# ble_rfcore_mdm_secure register map
Vendor: Texas Instruments
Peripheral module from a debugger description file (folder CC35X1).
Registers are 32-bit, access per field, reset 0x0 unless marked. A register's access mark holds for its fields unless they carry their own. Offsets are as the file gives them; lines under a group give offsets from that group; [hi:lo] are bit positions; {n}, {i} and the like mark numbered series; 'fields as' and 'values as' point back to an identical list; <NAME> marks a mode.

## ble_rfcore_mdm_secure (part 1 of 2)
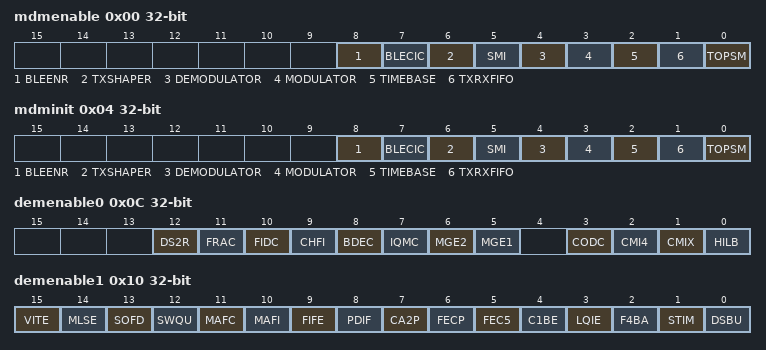
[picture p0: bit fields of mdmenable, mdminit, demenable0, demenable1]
0x00 mdmenable — Modem Enable Register
  [8] BLEENR rw — Enables the BLE ENR - Exp And Ramp (module location is in ble_top/ble_rfext/...)
  [7] BLECIC rw — Enables the BLE CIC (module location is in ble_top/ble_rfext/...)
  [6] TXSHAPER rw — Enables the BLE Tx-Shaper (module location is in ble_top/ble_rfext/...)
  [5] SMI rw — Enables the Serial Modem Interface
  [4] DEMODULATOR rw — Enables the Demodulator
  [3] MODULATOR rw — Enables the Modulator
  [2] TIMEBASE rw — Enables the Modem Timebase
  [1] TXRXFIFO rw — Enables the TX/RX FIFO
  [0] TOPSM rw — Enables the TOPsm (MCE)
0x04 mdminit — Modem Initialize Register - Each bit Initialize a specific MDM module Register type is WI ("Write Impulse"): Write generate 1-clock cycle pulse, Read 0.
  [8] BLEENR wo — Synch reset of the BLE ENR - Exp And Ramp (module location is in ble_top/ble_rfext/...)
  [7] BLECIC wo — Synch reset of the BLE CIC (module location is in ble_top/ble_rfext/...)
  [6] TXSHAPER wo — Synch reset for the BLE Tx-Shaper (module location is in ble_top/ble_rfext/...)
  [5] SMI wo — Synch reset Serial Modem Interface
  [4] DEMODULATOR wo — Synch reset Demodulator
  [3] MODULATOR wo — Synch reset Modulator
  [2] TIMEBASE wo — Synch reset Modem Timebase
  [1] TXRXFIFO wo — Synch reset TX/RX FIFO
  [0] TOPSM wo — Synch reset TOPsm (MCE)
0x08 mdmpdreq — Modem Power Down Request Register
  [0] TOPSMPDREQ rw — Requests power-down for TOPsm core. If the TOPsm has an ongoing memory access, the hardware will safely gate the clock after the transaction has completed.
0x0C demenable0 — Demodulator Enable Register 0
  [12] DS2R rw — Enables the DEC-S2R module
  [11] FRAC rw — Enables the fractional resampler
  [10] FIDC rw — Enables the fine DC estimator
  [9] CHFI rw — Enables the channel filter
  [8] BDEC rw — Enables the cascaded dec-by-2 stages (bde1 and bde2)
  [7] IQMC rw — Enables the IQ mismatch compensation
  [6] MGE2 rw — Enables the magnitude estimator engine #2
  [5] MGE1 rw — Enables the magnitude estimator engine #1
  [3] CODC rw — Enables the coarse DC estimator
  [2] CMI4 rw — Enables the 1/4 complex mixer
  [1] CMIX rw — Enables the N/1024 complex mixer
  [0] HILB rw — Enables the Hilbert filter
0x10 demenable1 — Demodulator Enable Register 1
  [15] VITE rw — Enables the Viterbi module
  [14] MLSE rw — Enables the MLSE module
  [13] SOFD rw — Enables the soft decision module
  [12] SWQU rw — Enables the sync word qualifier
  [11] MAFC rw — Enables the manual frequency compensation module
  [10] MAFI rw — Enables the matched filter
  [9] FIFE rw — Enables the fine frequency offset estimator
  [8] PDIF rw — Enables the phase differentiation
  [7] CA2P rw — Enables the cart 2 polar conversion
  [6] FECP rw — Enables the fecp module
  [5] FEC5 rw — Enables the fec5 module
  [4] C1BE rw — Enables the correlation 1-bit engine
  [3] LQIE rw — Enables the LQI engine
  [2] F4BA rw — Enables the clock-domain crossing fifo
  [1] STIM rw — Enables the symbol timing tracker
  [0] DSBU rw — Enables the dynamic sample buffer
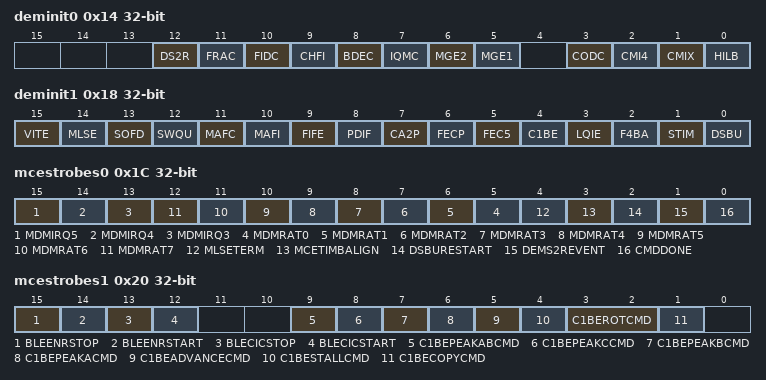
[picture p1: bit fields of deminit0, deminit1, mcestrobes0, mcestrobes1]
0x14 deminit0 — Demodulator Initialize Register 0 - Each bit Initialize a specific Demodulator module. Register type is WI ("Write Impulse"): Write generate 1-clock cycle pulse, Read 0.
  [12] DS2R wo — Synch reset DEC-S2R module
  [11] FRAC wo — Synch reset fractional resampler
  [10] FIDC wo — Synch reset fine DC estimator
  [9] CHFI wo — Synch reset channel filter
  [8] BDEC wo — Synch reset cascaded dec-by-2 stages (bde1 and bde2)
  [7] IQMC wo — Synch reset IQ mismatch compensation
  [6] MGE2 wo — Synch reset magnitude estimator engine #2
  [5] MGE1 wo — Synch reset magnitude estimator engine #1
  [3] CODC wo — Synch reset coarse DC estimator
  [2] CMI4 wo — Synch reset 1/4 complex mixer
  [1] CMIX wo — Synch reset N/1024 complex mixer
  [0] HILB wo — Synch reset Hilbert filter
0x18 deminit1 — Demodulator Initialize Register 1 - Each bit Initialize a specific Demodulator module. Register type is WI ("Write Impulse"): Write generate 1-clock cycle pulse, Read 0.
  [15] VITE wo — Synch reset Viterbi Module
  [14] MLSE wo — Synch reset MLSE module
  [13] SOFD wo — Synch reset soft decision module
  [12] SWQU wo — Synch reset sync word qualifyer
  [11] MAFC wo — Synch reset manual frequency compensation module
  [10] MAFI wo — Synch reset matched filter
  [9] FIFE wo — Synch reset fine frequency offset estimator
  [8] PDIF wo — Synch reset phase differentiation
  [7] CA2P wo — Synch reset cart 2 polar conversion
  [6] FECP wo — Synch reset fecp module
  [5] FEC5 wo — Synch reset fec5 module
  [4] C1BE wo — Synch reset correlation 1-bit engine
  [3] LQIE wo — Synch reset LQI engine
  [2] F4BA wo — Synch reset clock-domain crossing fifo
  [1] STIM wo — Synch reset symbol timing tracker
  [0] DSBU wo — Synch reset dynamic sample buffer
0x1C mcestrobes0 — Modem Command Engine (MCE) Strobe Register 0 - Each bit Strob a specific event. Register type is WI ("Write Impulse"): Write generate 1-clock cycle pulse, Read 0.
  [15] MDMIRQ5 wo — Firmware defined MDM IRQ 5 event
  [14] MDMIRQ4 wo — Firmware defined MDM IRQ 4 event
  [13] MDMIRQ3 wo — Firmware defined MDM IRQ 3 event
  [n+5] MDMRAT{n} wo (n=0..7) — Firmware defined MDM RAT {n} event
  [4] MLSETERM wo — Terminate MLSE unit
  [3] MCETIMBALIGN wo — Align the 1baud to the next 4baud event
  [2] DSBURESTART wo — Restart DSBU
  [1] DEMS2REVENT wo — Dem-S2R Trigger Event
  [0] CMDDONE wo — Signal command done to CPE
0x20 mcestrobes1 — Modem Command Engine (MCE) Strobe Register 1 - Each bit Strob a specific event. Register type is WI ("Write Impulse"): Write generate 1-clock cycle pulse, Read 0.
  [15] BLEENRSTOP wo — Trigger BLE ENR (Exp And Ramp) Stop - Ramp-Down
  [14] BLEENRSTART wo — Trigger BLE ENR (Exp And Ramp) Start - Ramp-Up
  [13] BLECICSTOP wo — Trigger BLE CIC Stop
  [12] BLECICSTART wo — Trigger BLE CIC Start
  [9] C1BEPEAKABCMD wo — Restart C1BE peak A and B search
  [8] C1BEPEAKCCMD wo — Restart C1BE peak C search (corr C is corr A+B combined = 64 symbols = 256 samples)
  [7] C1BEPEAKBCMD wo — Restart C1BE peak B search (32 symbols = 128 samples)
  [6] C1BEPEAKACMD wo — Restart C1BE peak A search (32 symbols = 128 samples)
  [5] C1BEADVANCECMD wo — Speed up correlator autocopy with one sample
  [4] C1BESTALLCMD wo — Slow down correlator autocopy with one sample
  [3:2] C1BEROTCMD wo — Correlator rotate command to shift reg B
    0=ROT0 (No additional rotation (normal shift-right mode)); 1=ROT1R (Rotate 1 sample to the right); 2=ROT1L (Rotate 1 sample to the left); 3=ROT16R (Rotate 16 samples to the right)
  [1] C1BECOPYCMD wo — Copy contents of shift reg A into shift reg B
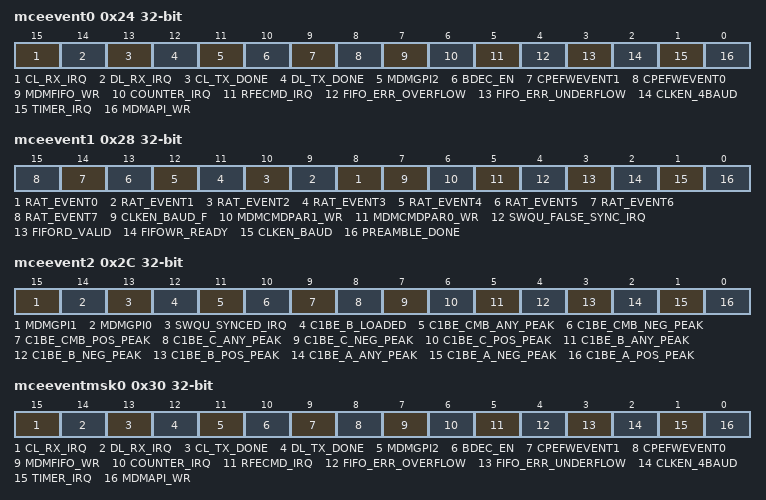
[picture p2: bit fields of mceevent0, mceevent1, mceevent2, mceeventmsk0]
0x24 mceevent0 ro — MCE Event Flag Register 0
  [15] CL_RX_IRQ — SMI serdes command word receive done
  [14] DL_RX_IRQ — SMI serdes data word receive done
  [13] CL_TX_DONE — SMI serdes command word transmit done
  [12] DL_TX_DONE — SMI serdes data word transmit done
  [11] MDMGPI2 — External input event line RFC_GPI_2 from IOC.
  [10] BDEC_EN — BDEC output enable event
  [9] CPEFWEVENT1 — Firmware defined event 1 from CPE
  [8] CPEFWEVENT0 — Firmware defined event 0 from CPE
  [7] MDMFIFO_WR — A write to the modem FIFO (via MDMFIFOWR register), probably by CPE
  [6] COUNTER_IRQ — Counter value reached in local timer
  [5] RFECMD_IRQ — New command from RFE received in RFERCEV register
  [4] FIFO_ERR_OVERFLOW — Modem FIFO overflow error event
  [3] FIFO_ERR_UNDERFLOW — Modem FIFO underflow error event
  [2] CLKEN_4BAUD — Clock enable event at 4 times baud rate
  [1] TIMER_IRQ — Timer period expired in local timer
  [0] MDMAPI_WR — New command from CPE has been written in MDMAPI register
0x28 mceevent1 ro — MCE Event Flag Register 1
  [n+8] RAT_EVENT{n} (n=0..7) — Radio timer event {n}
  [7] CLKEN_BAUD_F — Clock enable event at flushed baud rate
  [6] MDMCMDPAR1_WR — A write to MDMCMDPAR1 register, probably by CPE
  [5] MDMCMDPAR0_WR — A write to MDMCMDPAR0 register, probably by CPE
  [4] SWQU_FALSE_SYNC_IRQ — Sync word qualifier rejected sync due to bit errors (happens if a correlator event was due to noise)
  [3] FIFORD_VALID — Modem FIFO has valid data so a new word can be read from it, via MDMFIFORD
  [2] FIFOWR_READY — Modem FIFO is ready for more data so a new word can be written to it, via MDMFIFOWR register
  [1] CLKEN_BAUD — Clock enable event at baud rate
  [0] PREAMBLE_DONE — Preamble done interrupt from modulator
0x2C mceevent2 ro — MCE Event Flag Register 2
  [15] MDMGPI1 — External input event line RFC_GPI1 from IOC.
  [14] MDMGPI0 — External input event line RFC_GPI0 from IOC. (Also, when loopback mode is enabled in DEMDEBUG.LOOPBACKMODE, this input line represents the symbols fed to the demodulator's decode stage).
  [13] SWQU_SYNCED_IRQ — Sync word qualifier detected sync word.
  [12] C1BE_B_LOADED — C1BE correlator B loaded (by auto-copy function).
  [11] C1BE_CMB_ANY_PEAK — C1BE correlator AB combined, any peak detect: (abs(corr A) > thr A) and (abs(corr B) > thr B). Event occurs one sample after actual peak.
  [10] C1BE_CMB_NEG_PEAK — C1BE correlator AB combined, negative peak detect: (corr A < -thr A) and (corr B < -thr B). Event occurs one sample after actual peak.
  [9] C1BE_CMB_POS_PEAK — C1BE correlator AB combined, positive peak detect: (corr A > thr A) and (corr B > thr B). Event occurs one sample after actual peak.
  [8] C1BE_C_ANY_PEAK — C1BE correlator C, any peak detect: abs(corr C) > thr C. Event occurs one sample after actual peak.
  [7] C1BE_C_NEG_PEAK — C1BE correlator C, negative peak detect: corr C < -thr C. Event occurs one sample after actual peak.
  [6] C1BE_C_POS_PEAK — C1BE correlator C, positive peak detect: corr C > thr C. Event occurs one sample after actual peak.
  [5] C1BE_B_ANY_PEAK — C1BE correlator B, any peak detect: abs(corr B) > thr B. Event occurs one sample after actual peak.
  [4] C1BE_B_NEG_PEAK — C1BE correlator B, negative peak detect: corr B < -threshold B. Event occurs one sample after actual peak.
  [3] C1BE_B_POS_PEAK — C1BE correlator B, positive peak detect: corr B > threshold B. Event occurs one sample after actual peak.
  [2] C1BE_A_ANY_PEAK — C1BE correlator A, any peak detect: abs(corr A) > thr A. Event occurs one sample after actual peak.
  [1] C1BE_A_NEG_PEAK — C1BE correlator A, negative peak detect: corr A < -thr A. Event occurs one sample after actual peak.
  [0] C1BE_A_POS_PEAK — C1BE correlator A, positive peak detect: corr A > thr A. Event occurs one sample after actual peak.
0x30 mceeventmsk0 — MCE Event Mask Register 0
  [15] CL_RX_IRQ rw — Enable mask for event [MCEEVENT0.cl_rx_irq].
  [14] DL_RX_IRQ rw — Enable mask for event [MCEEVENT0.dl_rx_irq].
  [13] CL_TX_DONE rw — Enable mask for event [MCEEVENT0.cl_tx_done].
  [12] DL_TX_DONE rw — Enable mask for event [MCEEVENT0.dl_tx_done].
  [11] MDMGPI2 rw — Enable mask for event [MCEEVENT0.mdmgpi2].
  [10] BDEC_EN rw — Enable mask for event [MCEEVENT0.bdec_en].
  [9] CPEFWEVENT1 rw — Enable mask for event [MCEEVENT0.cpefwevent1].
  [8] CPEFWEVENT0 rw — Enable mask for event [MCEEVENT0.cpefwevent0].
  [7] MDMFIFO_WR rw — Enable mask for event [MCEEVENT0.mdmfifo_wr].
  [6] COUNTER_IRQ rw — Enable mask for event [MCEEVENT0.counter_irq].
  [5] RFECMD_IRQ rw — Enable mask for event [MCEEVENT0.rfecmd_irq].
  [4] FIFO_ERR_OVERFLOW rw — Enable mask for event [MCEEVENT0.fifo_err_overflow].
  [3] FIFO_ERR_UNDERFLOW rw — Enable mask for event [MCEEVENT0.fifo_err_underflow].
  [2] CLKEN_4BAUD rw — Enable mask for event [MCEEVENT0.clken_4baud].
  [1] TIMER_IRQ rw — Enable mask for event [MCEEVENT0.timer_irq].
  [0] MDMAPI_WR rw — Enable mask for event [MCEEVENT0.mdmapi_wr].
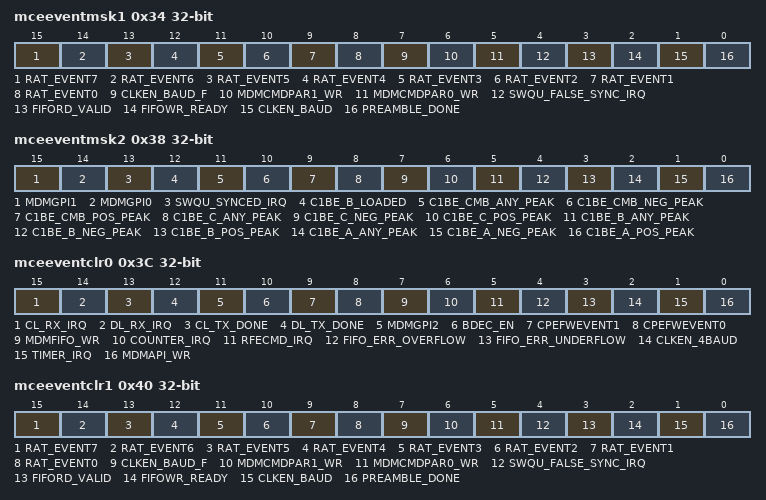
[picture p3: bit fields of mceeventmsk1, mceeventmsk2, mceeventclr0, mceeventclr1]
0x34 mceeventmsk1 — MCE Event Mask Register 1
  [15] RAT_EVENT7 rw — Enable mask for event [MCEEVENT1.rat_event7].
  [14] RAT_EVENT6 rw — Enable mask for event [MCEEVENT1.rat_event6].
  [13] RAT_EVENT5 rw — Enable mask for event [MCEEVENT1.rat_event5].
  [12] RAT_EVENT4 rw — Enable mask for event [MCEEVENT1.rat_event4].
  [11] RAT_EVENT3 rw — Enable mask for event [MCEEVENT1.rat_event3].
  [10] RAT_EVENT2 rw — Enable mask for event [MCEEVENT1.rat_event2].
  [9] RAT_EVENT1 rw — Enable mask for event [MCEEVENT1.rat_event1].
  [8] RAT_EVENT0 rw — Enable mask for event [MCEEVENT1.rat_event0].
  [7] CLKEN_BAUD_F rw — Enable mask for event [MCEEVENT1.clken_baud_f].
  [6] MDMCMDPAR1_WR rw — Enable mask for event [MCEEVENT1.mdmcmdpar1_wr].
  [5] MDMCMDPAR0_WR rw — Enable mask for event [MCEEVENT1.mdmcmdpar0_wr].
  [4] SWQU_FALSE_SYNC_IRQ rw — Enable mask for event [MCEEVENT1.swqu_false_sync_irq].
  [3] FIFORD_VALID rw — Enable mask for event [MCEEVENT1.fiford_valid].
  [2] FIFOWR_READY rw — Enable mask for event [MCEEVENT1.fifowr_valid].
  [1] CLKEN_BAUD rw — Enable mask for event [MCEEVENT1.clken_baud].
  [0] PREAMBLE_DONE rw — Enable mask for event [MCEEVENT1.preamble_done].
0x38 mceeventmsk2 — MCE Event Mask Register 2
  [15] MDMGPI1 rw — Enable mask for event [MCEEVENT2.mdmgpi1].
  [14] MDMGPI0 rw — Enable mask for event [MCEEVENT2.mdmgpi0].
  [13] SWQU_SYNCED_IRQ rw — Enable mask for event [MCEEVENT2.swqu_synced_irq].
  [12] C1BE_B_LOADED rw — Enable mask for event [MCEEVENT2.c1be_b_loaded].
  [11] C1BE_CMB_ANY_PEAK rw — Enable mask for event [MCEEVENT2.c1be_cmd_any_peak].
  [10] C1BE_CMB_NEG_PEAK rw — Enable mask for event [MCEEVENT2.c1be_cmd_neg_peak].
  [9] C1BE_CMB_POS_PEAK rw — Enable mask for event [MCEEVENT2.c1be_cmd_pos_peak].
  [8] C1BE_C_ANY_PEAK rw — Enable mask for event [MCEEVENT2.c1be_c_any_peak].
  [7] C1BE_C_NEG_PEAK rw — Enable mask for event [MCEEVENT2.c1be_c_neg_peak].
  [6] C1BE_C_POS_PEAK rw — Enable mask for event [MCEEVENT2.c1be_c_pos_peak].
  [5] C1BE_B_ANY_PEAK rw — Enable mask for event [MCEEVENT2.c1be_b_any_peak].
  [4] C1BE_B_NEG_PEAK rw — Enable mask for event [MCEEVENT2.c1be_b_neg_peak].
  [3] C1BE_B_POS_PEAK rw — Enable mask for event [MCEEVENT2.c1be_b_pos_peak].
  [2] C1BE_A_ANY_PEAK rw — Enable mask for event [MCEEVENT2.c1be_a_any_peak].
  [1] C1BE_A_NEG_PEAK rw — Enable mask for event [MCEEVENT2.c1be_a_neg_peak].
  [0] C1BE_A_POS_PEAK rw — Enable mask for event [MCEEVENT2.c1be_a_pos_peak].
0x3C mceeventclr0 — MCE Event Clear Register 0 - Each bit Clear to '0' a specific event. Register type is WI ("Write Impulse"): Write generate 1-clock cycle pulse, Read 0.
  [15] CL_RX_IRQ wo — Clear event [MCEEVENT0.cl_rx_irq].
  [14] DL_RX_IRQ wo — Clear event [MCEEVENT0.dl_rx_irq].
  [13] CL_TX_DONE wo — Clear event [MCEEVENT0.cl_tx_done].
  [12] DL_TX_DONE wo — Clear event [MCEEVENT0.dl_tx_done].
  [11] MDMGPI2 wo — Clear event [MCEEVENT0.mdmgpi2].
  [10] BDEC_EN wo — Clear event [MCEEVENT0.bdec_en].
  [9] CPEFWEVENT1 wo — Clear event [MCEEVENT0.cpefwevent1].
  [8] CPEFWEVENT0 wo — Clear event [MCEEVENT0.cpefwevent0].
  [7] MDMFIFO_WR wo — Clear event [MCEEVENT0.mdmfifo_wr].
  [6] COUNTER_IRQ wo — Clear event [MCEEVENT0.counter_irq].
  [5] RFECMD_IRQ wo — Clear event [MCEEVENT0.rfecmd_irq].
  [4] FIFO_ERR_OVERFLOW wo — Clear event [MCEEVENT0.fifo_err_overflow].
  [3] FIFO_ERR_UNDERFLOW wo — Clear event [MCEEVENT0.fifo_err_underflow].
  [2] CLKEN_4BAUD wo — Clear event [MCEEVENT0.clken_4baud].
  [1] TIMER_IRQ wo — Clear event [MCEEVENT0.timer_irq].
  [0] MDMAPI_WR wo — Clear event [MCEEVENT0.mdmapi_wr].
0x40 mceeventclr1 — MCE Event Clear Register 1 - Each bit Clear to '0' a specific event. Register type is WI ("Write Impulse"): Write generate 1-clock cycle pulse, Read 0.
  [15] RAT_EVENT7 wo — Clear event [MCEEVENT1.rat_event7].
  [14] RAT_EVENT6 wo — Clear event [MCEEVENT1.rat_event6].
  [13] RAT_EVENT5 wo — Clear event [MCEEVENT1.rat_event5].
  [12] RAT_EVENT4 wo — Clear event [MCEEVENT1.rat_event4].
  [11] RAT_EVENT3 wo — Clear event [MCEEVENT1.rat_event3].
  [10] RAT_EVENT2 wo — Clear event [MCEEVENT1.rat_event2].
  [9] RAT_EVENT1 wo — Clear event [MCEEVENT1.rat_event1].
  [8] RAT_EVENT0 wo — Clear event [MCEEVENT1.rat_event0].
  [7] CLKEN_BAUD_F wo — Clear event [MCEEVENT1.clken_baud_f].
  [6] MDMCMDPAR1_WR wo — Clear event [MCEEVENT1.mdmcmdpar1_wr].
  [5] MDMCMDPAR0_WR wo — Clear event [MCEEVENT1.mdmcmdpar0_wr].
  [4] SWQU_FALSE_SYNC_IRQ wo — Clear event [MCEEVENT1.swqu_false_sync_irq].
  [3] FIFORD_VALID wo — Clear event [MCEEVENT1.fiford_valid].
  [2] FIFOWR_READY wo — Clear event [MCEEVENT1.fifowr_valid].
  [1] CLKEN_BAUD wo — Clear event [MCEEVENT1.clken_baud].
  [0] PREAMBLE_DONE wo — Clear event [MCEEVENT1.preamble_done].
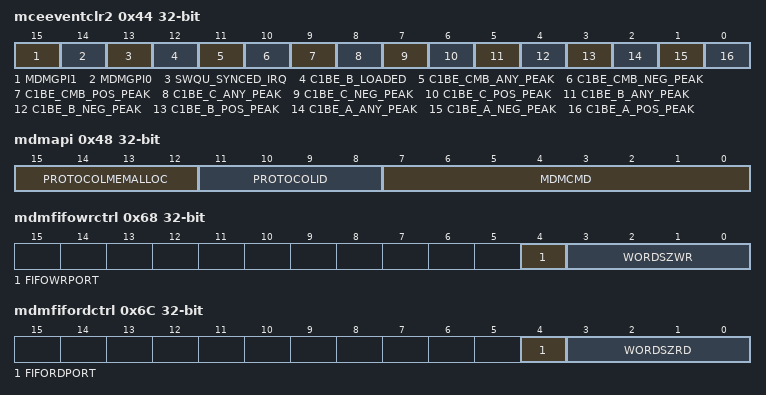
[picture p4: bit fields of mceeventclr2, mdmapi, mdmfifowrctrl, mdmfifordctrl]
0x44 mceeventclr2 — MCE Event Clear Register 2 - Each bit Clear to '0' a specific event. Register type is WI ("Write Impulse"): Write generate 1-clock cycle pulse, Read 0.
  [15] MDMGPI1 wo — Clear event [MCEEVENT2.mdmgpi1].
  [14] MDMGPI0 wo — Clear event [MCEEVENT2.mdmgpi0].
  [13] SWQU_SYNCED_IRQ wo — Clear event [MCEEVENT2.swqu_synced_irq].
  [12] C1BE_B_LOADED wo — Clear event [MCEEVENT2.c1be_b_loaded].
  [11] C1BE_CMB_ANY_PEAK wo — Clear event [MCEEVENT2.c1be_cmd_any_peak].
  [10] C1BE_CMB_NEG_PEAK wo — Clear event [MCEEVENT2.c1be_cmd_neg_peak].
  [9] C1BE_CMB_POS_PEAK wo — Clear event [MCEEVENT2.c1be_cmd_pos_peak].
  [8] C1BE_C_ANY_PEAK wo — Clear event [MCEEVENT2.c1be_c_any_peak].
  [7] C1BE_C_NEG_PEAK wo — Clear event [MCEEVENT2.c1be_c_neg_peak].
  [6] C1BE_C_POS_PEAK wo — Clear event [MCEEVENT2.c1be_c_pos_peak].
  [5] C1BE_B_ANY_PEAK wo — Clear event [MCEEVENT2.c1be_b_any_peak].
  [4] C1BE_B_NEG_PEAK wo — Clear event [MCEEVENT2.c1be_b_neg_peak].
  [3] C1BE_B_POS_PEAK wo — Clear event [MCEEVENT2.c1be_b_pos_peak].
  [2] C1BE_A_ANY_PEAK wo — Clear event [MCEEVENT2.c1be_a_any_peak].
  [1] C1BE_A_NEG_PEAK wo — Clear event [MCEEVENT2.c1be_a_neg_peak].
  [0] C1BE_A_POS_PEAK wo — Clear event [MCEEVENT2.c1be_a_pos_peak].
0x48 mdmapi — Modem API Command Register
  [15:12] PROTOCOLMEMALLOC rw — Protocol Memory Allocation. 0000 : For Default MCE Execution - mem allocation of addr lines 0-511 (lower 2k bank). 0001 : For MCE Execution with mem allocation of addr lines 512-1023 (higher 2k bank). (NOTE - NEW Osprey Field. In legacy projects was PROTOCOLID[7:4] which Never used.)
  [11:8] PROTOCOLID rw
  [7:0] MDMCMD rw — Modem command
0x4C mdmcmdpar0 — Modem API Command Parameter 0
  [15:0] PAR0 rw — Parameter 0. Software defined function.
0x50 mdmcmdpar1 — Modem API Command Parameter 1
  [15:0] PAR1 rw — Parameter 1. Software defined function.
0x54 mdmcmdpar2 — Modem API Command Parameter 2
  [15:0] PAR rw — Parameter 2. Software defined function.
0x58 mdmrfchannel — Modem RF Channel Register
  [11:0] VALUE rw — RF channel in MHz (i.e. 2432). This register is only software defined for signalling RF channel.
0x5C mdmstatus — Modem Command Status Register
  [15:0] VALUE rw — Diverse status, error, report bits from MCE. Controlled by software.
0x60 mdmfifowr — Modem FIFO Write Register
  [15:0] PAYLOADIN rw — FIFO write port. The actual port size is configurable in MDMFIFOWRCTRL.FIFOWRCTRL.
0x64 mdmfiford ro — Modem FIFO Read Register
  [15:0] PAYLOADOUT — FIFO read port. The actual port size is configurable in MDMFIFORDCTRL.FIFORDCTRL.
0x68 mdmfifowrctrl — Modem FIFO Write Configuration
  [4] FIFOWRPORT rw — FIFO write port mapping
    0=MDMFIFOWR (The MDMFIFOWR register is used for write access); 1=MODEM (Modem has write access)
  [3:0] WORDSZWR rw — Actual bits in every word write access
    0=BITS1 (1 bit); {v}=BITS{v+1} ({v+1} bits) (v=1..15)
0x6C mdmfifordctrl — Modem FIFO Read Configuration
  [4] FIFORDPORT rw — FIFO read port mapping
    0=MDMFIFORD (The MDMFIFORD register is used for read access); 1=MODEM (Modem has read access)
  [3:0] WORDSZRD rw — Actual bits in every word read access
    0=BITS1 (1 bit); {v}=BITS{v+1} ({v+1} bits) (v=1..15)
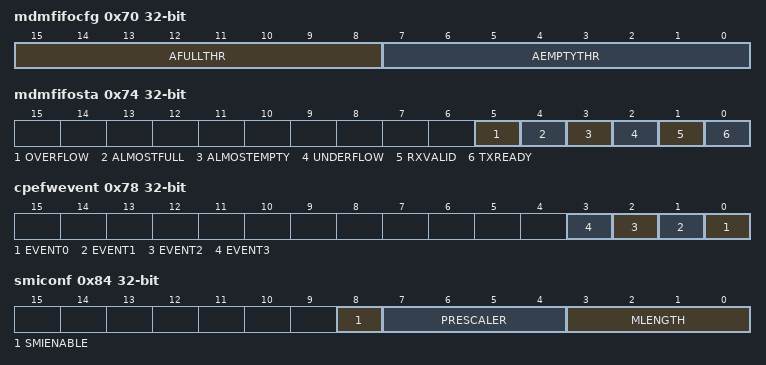
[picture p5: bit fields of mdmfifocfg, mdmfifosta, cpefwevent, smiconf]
0x70 mdmfifocfg — Modem FIFO Configuration for watermark thresholds
  [15:8] AFULLTHR rw — Almost full threshold value in bits. This threshold affects the MDMFIFOSTA.ALMOSTFULL and MDMFIFOSTA.TXREADY status bits. The FIFO can hold up to 64 bits.
  [7:0] AEMPTYTHR rw — Almost empty threshold in bits. This threshold affects the MDMFIFOSTA.ALMOSTEMPTY and MDMFIFOSTA.RXVALID status bits. The FIFO can hold up to 64 bits.
0x74 mdmfifosta ro — Modem FIFO Status Flags
  [5] OVERFLOW — FIFO overflow error. If this flag is asserted the modem FIFO must be re-initialized with MDMINIT.TXRXFIFO to clear it. Note that re-initializing will flush the FIFO.
  [4] ALMOSTFULL — FIFO is almost full. Asserts when the FIFO fill level is above the almost full threshold.
  [3] ALMOSTEMPTY — FIFO is almost empty. Asserts when the FIFO fill level is below the almost empty threshold.
  [2] UNDERFLOW — FIFO underflow error. If this flag is asserted the modem FIFO must be re-initialized with MDMINIT.TXRXFIFO to clear it.
  [1] RXVALID — A full data word is valid and can be read in MDMRXFIFO register read port.
  [0] TXREADY — The MDMTXFIFO register write port is ready to receive a data word.
0x78 cpefwevent — CPE-to-MCE Firmware Triggered Events - Each bit Trigger a specific event. Register type is WI ("Write Impulse"): Write generate 1-clock cycle pulse, Read 0.
  [n] EVENT{n} wo (n=0..3) — Generic FW CPE-driven event to MCE. Software defined meaning.
0x7C rfesend — MCE-to-RFE Send Command Register
  [15:0] MCECMD rw — Command to send to RFE. Writing to this register will trigger an event in the RFE, and the command value written here will be readable in RFC_RFE:MCERCEV register.
0x80 rfercev ro — RFE-to-MCE Receive Command Register
  [15:0] RFECMD — Command received from RFE
0x84 smiconf — Serial Modem Interface Configuration
  [8] SMIENABLE rw — Enables the SMI interface
  [7:4] PRESCALER rw — Configures the SMI rate
  [3:0] MLENGTH rw — Configures the Message Length
0x88 smidloutg — Serial Modem Interface Data Output Register
  [15:0] DL rw — Outgoing data link message
0x8C smicloutg — Serial Modem Interface Control Output Register
  [15:0] CL rw — Outgoing command link message
0x90 smidlinc ro — Serial Modem Interface Data Input Register
  [15:0] DL — Incoming data link message
0x94 smiclinc ro — Serial Modem Interface Control Input Register
  [15:0] CL — Incoming command link message
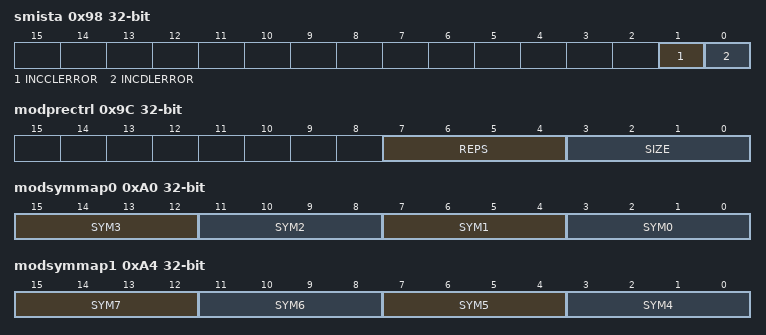
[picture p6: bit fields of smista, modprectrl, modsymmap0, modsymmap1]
0x98 smista ro — Serial Modem Interface Status Register
  [1] INCCLERROR — Incoming command link has errors
  [0] INCDLERROR — Incoming data link has errors
0x9C modprectrl — Modulator Preamble Control
  [7:4] REPS rw — Number of preamble repetitions of preamble pattern
    0=1 repetition (i.e. only once); {v}={v+1} repetitions (v=1..15)
  [3:0] SIZE rw — Preamble pattern size in bits
    15=BITS16 (16 bits); 3=BITS4 (4 bits); 7=BITS8 (8 bits)
0xA0 modsymmap0 — Modulator Symbol Mapping Register 0
  [15:12] SYM3 rw — Decimal value for bits '11'
  [11:8] SYM2 rw — Decimal value for bits '01'
  [7:4] SYM1 rw — Decimal value for bit '1'
  [3:0] SYM0 rw — Decimal value for bit '0'
0xA4 modsymmap1 — Modulator Symbol Mapping Register 1
  [15:12] SYM7 rw — Decimal value for bits '111'
  [11:8] SYM6 rw — Decimal value for bits '110'
  [7:4] SYM5 rw — Decimal value for bits '101'
  [3:0] SYM4 rw — Decimal value for bits '100'
0xA8 modsofttx — Modulator Soft Symbol Transmit
  [3:0] SOFTSYMBOL rw — Soft symbol {-7..+7} used when MODCTRL.SOFTTXENABLE is enabled
0xAC mdmbaud — Modem Baud Rate Control
  [15:0] RATEWORD rw — Rate word (bits [20:5]). The 5 LSBs of the 21-bit rate word are defined in MDMBAUDPRE.EXTRATEWORD register.
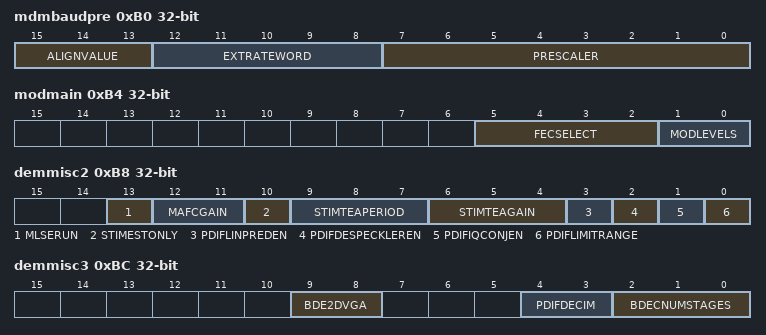
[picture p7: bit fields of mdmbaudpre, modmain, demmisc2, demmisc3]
0xB0 mdmbaudpre — Modem Baud Rate Prescaler Control
  [15:13] ALIGNVALUE rw — Align value for timebase after sync
  [12:8] EXTRATEWORD rw — Extended Rate Word (bits [4:0]). These are the 5 LSBs extending the 16 MSBs configured in MDMBAUD.RATEWORD to form a 21 bit rate word.
  [7:0] PRESCALER rw — Prescaler value, range 1 to 255
0xB4 modmain — Modulator Main Config Register
  [5:2] FECSELECT rw — Forward Error Correction Selection. Used for some signal-wiring in modulator and demodulator.
    0=NOSEL (No FEC encoding selected); 1=IEEE15_4 (IEEE 802.15.4); 2=CC85XX (CC85xx compatible FEC); 3=BLR (Bluetooth LE coded long range compatible FEC); 4=SPREAD; 5=FEC13 (1/3 repetition code); 6=FEC23 (10/15 BT BR FEC 2/3 Mode); 7=MLSE4; 8=IEEE15_4G_NOREC (IEEE 802.15.4g non-recursive code); 9=IEEE15_4G_REC (IEEE 802.15.4g recursive code)
  [1:0] MODLEVELS rw — Number of modulation levels
    0=LVL2 (2 levels); 1=LVL4 (4 levels); 2=LVL8 (8 levels)
0xB8 demmisc2 — Demodulator Config Register 2
  [13] MLSERUN rw — Enable maximum likelihood sequence estimation (MLSE) desicions
  [12:11] MAFCGAIN rw — Set gain in MAFC. Multiplies symbols with 2^N before symbol recovery stage
  [10] STIMESTONLY rw — Only perform symbol timing error estimation in STIM, without doing timing correction
    0=DIS (Perform both estimation and correct timing); 1=EN (Perform estimation only (no timing correction))
  [9:7] STIMTEAPERIOD rw — Symbol timing error accumulator period (4 to 128 symbols) in STIM
    0=SYM4 (4 symbols); 1=SYM8 (8 symbols); 2=SYM16 (16 symbols); 3=SYM32 (32 symbols); 4=SYM64 (64 symbols); 5=SYM128 (128 symbols)
  [6:4] STIMTEAGAIN rw — Symbol timing error accumulator gain in STIM
    0=DIV512 (Gain is 1/512); 1=DIV256 (Gain is 1/256); 2=DIV128 (Gain is 1/128); 3=DIV64 (Gain is 1/64); 4=DIV32 (Gain is 1/32); 5=DIV16 (Gain is 1/16); 6=DIV8 (Gain is 1/8); 7=DIV4 (Gain is 1/4)
  [3] PDIFLINPREDEN rw — Enable linear predictor in PDIF at CORDIC output
  [2] PDIFDESPECKLEREN rw — Enable despeckler in PDIF at CORDIC output
  [1] PDIFIQCONJEN rw — Conjugate the complex I/Q signal in PDIF
  [0] PDIFLIMITRANGE rw — Limit range on maximal PDIF output, i.e. instantaneous frequency sample
    0=DIS (Allow full 8-bit range, i.e. +/- 128); 1=EN (Limit the range to 7-bit, i.e. +/- 64)
0xBC demmisc3 — Demodulator Config Register 3
  [9:8] BDE2DVGA rw — DVGA settings for BDE2. The DVGA control for BDE2 is shared with the RFE in its RFC_RFE:GAINCTRL.BDE2DVGA register. Software should determine who uses them. Please note that if both processors attempt to control it, the resulting setting will be the two settings ORed together.
    0=GAIN1; 1=GAIN2; 2=GAIN4; 3=GAIN8
  [4:3] PDIFDECIM rw — Additional decimation in PDIF
    0=DIV1 (No decimation); 1=DIV2 (Decimate by 2); 2=DIV4 (Decimate by 4)
  [2:0] BDECNUMSTAGES rw — BDE2 decimation filter setting
    0=DIV1 (Decimate by 1 (no decimation)); 1=DIV2 (Decimate by 2); 2=DIV4 (Decimate by 4); 3=DIV8 (Decimate by 8); 4=DIV16 (Decimate by 16); 5=DIV32 (Decimate by 32)
0xC0 demdsbu — Dynamic Sample Buffer Config Register
  [7:0] DSBUDELAY rw — Output delay from sample buffer, as offset between write and read pointers. The buffer can hold up to 256 samples. Delay of 0 means maximum.
0xC4 demdsbu2 — Dynamic Sample Buffer Config Register
  [7:0] DSBUAVGLENGTH rw — Length for moving average of the newest DSBU samples. The buffer can hold up to 256 samples. Length of 511 is maximum.
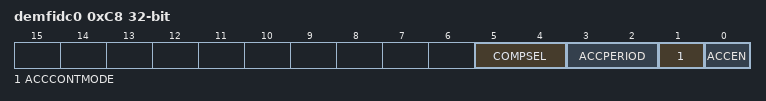
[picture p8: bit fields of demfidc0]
0xC8 demfidc0 — Demodulator Fine DC Offset Estimator Register 0
  [5:4] COMPSEL rw — Select estimator to use for fine DC offset compensation
    0=MANUAL (Use manually programmable values from DEMFIDC1 and DEMFIDC2 registers); 2=ACC (Compensate with latest accumulator estimate)
  [3:2] ACCPERIOD rw — Integration period for accumulator estimator
    0=SMPL8 (8 samples); 1=SMPL32 (32 samples); 2=SMPL128 (128 samples); 3=SMPL512 (512 samples)
  [1] ACCCONTMODE rw — Accumulator estimator mode
    0=SINGLE (Generate a single DC estimate only, then stop); 1=CONT (Generate new DC estimates continuously)
  [0] ACCEN rw — Enable accumulator based estimator inside FIDC
    0=DIS (Disable accumulator estimator); 1=EN (Enable accumulator estimator)
